# axidma register map
File version: 7.1
axidma device descript
Registers are 32-bit, read-write, reset 0x0 unless marked. A register's access mark holds for its fields unless they carry their own. Offsets are from the block's base; lines under a group give offsets from that group; [hi:lo] are bit positions; {n}, {i} and the like mark numbered series; 'fields as' and 'values as' point back to an identical list; <NAME> marks a mode.

## Memory map
0x00000000 MM2S_SG_DESC — Scatter Gather Descriptor
0x00000000 S2MM_SG_DESC — Scatter Gather Descriptor
0x60100000 AXI_DMA size 0x10000 — AXI Direct Memory Access

## MM2S_SG_DESC — Scatter Gather Descriptor
Base 0x00000000
0x00 nxt_desc — Next Descriptor Pointer
  [31:6] nxt_desc_ptr — Indicates the lower order pointer pointing to the first word of the next descriptor
0x04 nxt_desc_msb — Upper 32 bits of Next Descriptor Pointer
  [31:0] nxt_desc_ptr — Indicates the MSB 32 bits of the pointer pointing to the first word of the next descriptor
0x08 buf_addr — Buffer Address
  [31:0] buf_addr — Provides the location of the data to transfer from Memory Map to Stream.
0x0C buf_addr_msb — Upper 32 bits of Buffer Address
  [31:0] buf_addr — Provides the MSB 32 bits of the location of the data to transfer from Memory Map to Stream.
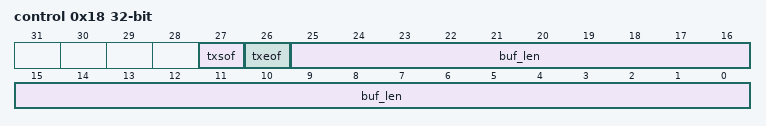
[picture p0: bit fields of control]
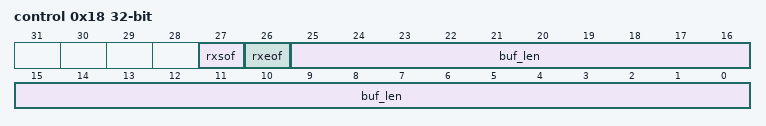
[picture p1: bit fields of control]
0x18 control
  [27] txsof — Start of Frame. Flag indicating the first buffer to be processed. This flag is set by the CPU to indicate to AXI DMA that this descriptor describes the start of the packet.
    0=NONE; 1=TXSOF
  [26] txeof — End of Frame. Flag indicating the last buffer to be processed. This flag is set by the CPU to indicate to AXI DMA that this descriptor describes the end of the packet.
    0=NONE; 1=TXEOF
  [25:0] buf_len — Indicates the size in bytes of the transfer buffer. This value indicates the amount of bytes to transmit out on the MM2S stream.
0x1C status ro
  [30] dma_dec_err — DMA Decode Error. Decode Error detected by primary AXI DataMover. This error occurs if the Descriptor Buffer Address points to an invalid address.
    0=NO_ERR; 1=DETECTED
  [29] dma_slv_err — DMA Slave Error. Slave Error detected by primary AXI DataMover. This error occurs if the slave read from the Memory Map interface issues a Slave Error.
    0=NO_ERR; 1=DETECTED
  [29] cmplt — Completed. This indicates to the software that the DMA Engine has completed the transfer as described by the associated descriptor.
    0=FALSE; 1=TRUE
  [28] dma_int_err — DMA Internal Error. Internal Error detected by primary AXI DataMover. This error can occur if a 0 length bytes to transfer is fed to the AXI DataMover.
    0=NO_ERR; 1=DETECTED
  [25:0] tfer_bytes — Indicates the size in bytes of the actual data transferred for this descriptor. This value indicates the amount of bytes to transmit out on MM2S stream.
{0x20+4i} app[{i}] (i=0..4) ro — User Application Field [{i}]
  [31:0] app — Specifies user-specific application data. When Status Control Stream is enabled, the Application (APP) fields of the Start of Frame (SOF) Descriptor are transmitted to the AXI Control Stream.

## S2MM_SG_DESC — Scatter Gather Descriptor
Base 0x00000000
0x00 nxt_desc — Next Descriptor Pointer
  [31:6] nxt_desc_ptr — Indicates the lower order pointer pointing to the first word of the next descriptor
0x04 nxt_desc_msb — Upper 32 bits of Next Descriptor Pointer
  [31:0] nxt_desc_ptr — Indicates the MSB 32 bits of the pointer pointing to the first word of the next descriptor
0x08 buf_addr — Buffer Address
  [31:0] buf_addr — Provides the location of the data to transfer from Stream to Memory Map.
0x0C buf_addr_msb — Upper 32 bits of Buffer Address
  [31:0] buf_addr — Provides the MSB 32 bits of the location of the data to transfer from Stream to Memory Map.
0x18 control
  [27] rxsof — Start of Frame. Flag indicating the first buffer to be processed. This flag is set by the sw/user to indicate to AXI DMA that this descriptor describes the start of the packet.
    0=FALSE; 1=TRUE
  [26] rxeof — End of Frame. Flag indicating the last buffer to be processed. This flag is set by the sw/user to indicate to AXI DMA that this descriptor describes the end of the packet.
    0=FALSE; 1=TRUE
  [25:0] buf_len — Indicates the amount of space in bytes available for receiving data in an S2MM stream.
0x1C status ro
  [30] dma_dec_err — DMA Decode Error. Decode Error detected by primary AXI DataMover. This error occurs if the Descriptor Buffer Address points to an invalid address.
    0=NO_ERR; 1=DETECTED
  [29] dma_slv_err — DMA Slave Error. Slave Error detected by primary AXI DataMover. This error occurs if the slave read from the Memory Map interface issues a Slave Error.
    0=NO_ERR; 1=DETECTED
  [29] cmplt — Completed. This indicates to the software that the DMA Engine has completed the transfer as described by the associated descriptor.
    0=FALSE; 1=TRUE
  [28] dma_int_err — DMA Internal Error. Internal Error detected by primary AXI DataMover. This error can occur if a 0 length bytes to transfer is fed to the AXI DataMover.
    0=NO_ERR; 1=DETECTED
  [27] rxsof — Start of Frame. Flag indicating buffer holds first part of packet. This bit is set by AXI DMA to indicate to the sw/user that the buffer associated with this descriptor contains the start of the packet.
    0=FALSE; 1=TRUE
  [26] rxeof — End of Frame. Flag indicating buffer holds the last part of packet. This bit is set by AXI DMA to indicate to the sw/user that the buffer associated with this descriptor contains the end of the packet.
    0=FALSE; 1=TRUE
  [25:0] tfer_bytes — This value indicates the amount of data received and stored in the buffer described by this descriptor. This might or might not match the buffer length.
{0x20+4i} app[{i}] (i=0..4) ro — User Application Field [{i}]
  [31:0] app — Specifies user-specific application data. When Status Control Stream is enabled, the Application (APP) fields of the Start of Frame (SOF) Descriptor are transmitted to the AXI Control Stream.
